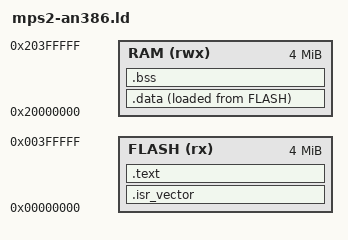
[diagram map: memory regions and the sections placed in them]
ENTRY(Reset_Handler)
MEMORY {
    FLASH (rx)  : ORIGIN = 0x00000000, LENGTH = 4M
    RAM (rwx)   : ORIGIN = 0x20000000, LENGTH = 4M
}
_estack = ORIGIN(RAM) + LENGTH(RAM);
SECTIONS {
    .isr_vector : { KEEP(*(.isr_vector)) } > FLASH
    .text : { *(.text*) *(.rodata*) . = ALIGN(4); } > FLASH
    .data : { . = ALIGN(4); _sdata = .; *(.data*) . = ALIGN(4); _edata = .; } > RAM AT > FLASH
    _sidata = LOADADDR(.data);
    .bss (NOLOAD) : { . = ALIGN(4); _sbss = .; *(.bss*) *(COMMON) . = ALIGN(8); _ebss = .; } > RAM
}
ASSERT(_ebss + 131072 < _estack, "insufficient stack")
